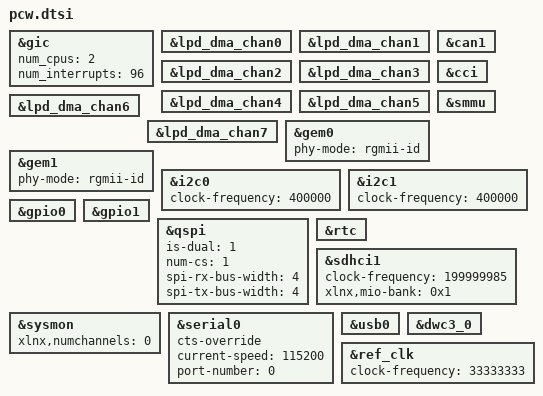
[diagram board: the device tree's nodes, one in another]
/*
 * CAUTION: This file is automatically generated by Xilinx.
 * Version:  
 * Today is: Mon Sep  6 15:35:58 2021
 */


&gic {
	num_cpus = <2>;
	num_interrupts = <96>;
};
&lpd_dma_chan0 {
	status = "okay";
};
&lpd_dma_chan1 {
	status = "okay";
};
&lpd_dma_chan2 {
	status = "okay";
};
&lpd_dma_chan3 {
	status = "okay";
};
&lpd_dma_chan4 {
	status = "okay";
};
&lpd_dma_chan5 {
	status = "okay";
};
&lpd_dma_chan6 {
	status = "okay";
};
&lpd_dma_chan7 {
	status = "okay";
};
&can1 {
	status = "okay";
};
&gem0 {
	phy-mode = "rgmii-id";
	status = "okay";
};
&gem1 {
	phy-mode = "rgmii-id";
	status = "okay";
};
&cci {
	status = "okay";
};
&smmu {
	status = "okay";
};
&i2c0 {
	clock-frequency = <400000>;
	status = "okay";
};
&i2c1 {
	clock-frequency = <400000>;
	status = "okay";
};
&gpio0 {
	status = "okay";
};
&gpio1 {
	status = "okay";
};
&qspi {
	is-dual = <1>;
	num-cs = <1>;
	spi-rx-bus-width = <4>;
	spi-tx-bus-width = <4>;
	status = "okay";
};
&rtc {
	status = "okay";
};
&sdhci1 {
	clock-frequency = <199999985>;
	status = "okay";
	xlnx,mio-bank = <0x1>;
};
&sysmon {
	#address-cells = <1>;
	#size-cells = <0>;
	xlnx,numchannels = /bits/8 <0>;
};
&serial0 {
	cts-override ;
	current-speed = <115200>;
	device_type = "serial";
	port-number = <0>;
	status = "okay";
};
&usb0 {
	status = "okay";
};
&dwc3_0 {
	status = "okay";
};
&ref_clk {
	clock-frequency = <33333333>;
};
